AUTOSAR XML (schema 4-2-2)
package /ComponentTypes
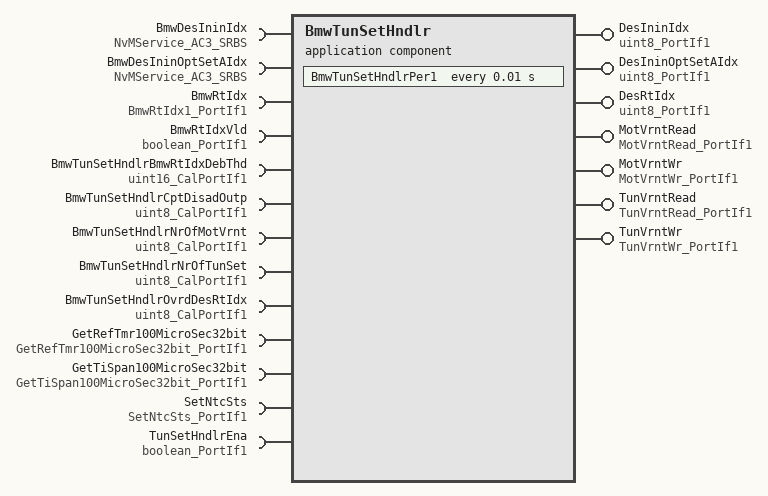
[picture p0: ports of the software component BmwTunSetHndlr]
  application sw component type BmwTunSetHndlr
    7 x provide port:
      DesIninIdx: nonqueued-sender-com-spec{data-element=Val, init-value=0}, provided-interface=uint8_PortIf1
      DesIninOptSetAIdx: nonqueued-sender-com-spec{data-element=Val, init-value=0}, provided-interface=uint8_PortIf1
      DesRtIdx: nonqueued-sender-com-spec{data-element=Val, init-value=0}, provided-interface=uint8_PortIf1
      MotVrntRead: server-com-spec{operation=Oper, queue-length=1}, provided-interface=MotVrntRead_PortIf1
      MotVrntWr: server-com-spec{operation=Oper, queue-length=1}, provided-interface=MotVrntWr_PortIf1
      TunVrntRead: server-com-spec{operation=Oper, queue-length=1}, provided-interface=TunVrntRead_PortIf1
      TunVrntWr: server-com-spec{operation=Oper, queue-length=1}, provided-interface=TunVrntWr_PortIf1
    13 x require port:
      BmwDesIninIdx: required-com-specs=[EraseBlock, GetErrorStatus, InvalidateNvBlock, ReadBlock, SetRamBlockStatus, WriteBlock], required-interface=NvMService_AC3_SRBS
      BmwDesIninOptSetAIdx: required-com-specs=[EraseBlock, GetErrorStatus, InvalidateNvBlock, ReadBlock, SetRamBlockStatus, WriteBlock], required-interface=NvMService_AC3_SRBS
      BmwRtIdx: nonqueued-receiver-com-spec{data-element=Val, filter=data-filter-type=ALWAYS, init-value=15}, required-interface=BmwRtIdx1_PortIf1
      BmwRtIdxVld: nonqueued-receiver-com-spec{data-element=Logl, filter=data-filter-type=ALWAYS, init-value=0}, required-interface=boolean_PortIf1
      BmwTunSetHndlrBmwRtIdxDebThd: parameter-require-com-spec{init-value=120, parameter=Val}, required-interface=uint16_CalPortIf1
      BmwTunSetHndlrCptDisadOutp: parameter-require-com-spec{init-value=0, parameter=Val}, required-interface=uint8_CalPortIf1
      BmwTunSetHndlrNrOfMotVrnt: parameter-require-com-spec{init-value=4, parameter=Val}, required-interface=uint8_CalPortIf1
      BmwTunSetHndlrNrOfTunSet: parameter-require-com-spec{init-value=7, parameter=Val}, required-interface=uint8_CalPortIf1
      BmwTunSetHndlrOvrdDesRtIdx: parameter-require-com-spec{init-value=5, parameter=Val}, required-interface=uint8_CalPortIf1
      GetRefTmr100MicroSec32bit: client-com-spec=Oper, required-interface=GetRefTmr100MicroSec32bit_PortIf1
      GetTiSpan100MicroSec32bit: client-com-spec=Oper, required-interface=GetTiSpan100MicroSec32bit_PortIf1
      SetNtcSts: client-com-spec=Oper, required-interface=SetNtcSts_PortIf1
      TunSetHndlrEna: nonqueued-receiver-com-spec{data-element=Logl, filter=data-filter-type=ALWAYS, init-value=1}, required-interface=boolean_PortIf1
    behavior BmwTunSetHndlr_InternalBehavior
      ar-typed-per-instance-memorys:
        6 x data, all with sw-calibration-access=READ-ONLY:
          BmwDesIninIdx: type=BmwDesIninIdxRec1
          BmwDesIninOptSetAIdx: type=BmwDesIninOptSetAIdxRec1
          BmwRtIdxTi: type=uint32
          DebBmwRtIdx: type=BmwRtIdx1
          LstVldIdx: type=uint8
          PrevBmwRtIdx: type=BmwRtIdx1
      init event BmwTunSetHndlr_InitEvent: start-on-event=BmwTunSetHndlrInit1
      timing event TMT_BmwTunSetHndlrPer1: start-on-event=BmwTunSetHndlrPer1, period=0.01
      4 x operation invoked event:
        OIT_MotVrntRead_Oper_MotVrntRead_Oper: start-on-event=MotVrntRead_Oper, operation=MotVrntRead.Oper
        OIT_MotVrntWr_Oper_MotVrntWr_Oper: start-on-event=MotVrntWr_Oper, operation=MotVrntWr.Oper
        OIT_TunVrntRead_Oper_TunVrntRead_Oper: start-on-event=TunVrntRead_Oper, operation=TunVrntRead.Oper
        OIT_TunVrntWr_Oper_TunVrntWr_Oper: start-on-event=TunVrntWr_Oper, operation=TunVrntWr.Oper
      port-api-options:
        enable-take-address=false, error-handling=NO-TRANSFORMER-ERROR-HANDLING, indirect-api=false, port=BmwDesIninIdx
        enable-take-address=false, error-handling=NO-TRANSFORMER-ERROR-HANDLING, indirect-api=false, port=BmwRtIdx
        enable-take-address=false, error-handling=NO-TRANSFORMER-ERROR-HANDLING, indirect-api=false, port=BmwRtIdxVld
        enable-take-address=false, error-handling=NO-TRANSFORMER-ERROR-HANDLING, indirect-api=false, port=BmwTunSetHndlrBmwRtIdxDebThd
        enable-take-address=false, error-handling=NO-TRANSFORMER-ERROR-HANDLING, indirect-api=false, port=BmwTunSetHndlrCptDisadOutp
        enable-take-address=false, error-handling=NO-TRANSFORMER-ERROR-HANDLING, indirect-api=false, port=BmwTunSetHndlrNrOfMotVrnt
        enable-take-address=false, error-handling=NO-TRANSFORMER-ERROR-HANDLING, indirect-api=false, port=BmwTunSetHndlrOvrdDesRtIdx
        enable-take-address=false, error-handling=NO-TRANSFORMER-ERROR-HANDLING, indirect-api=false, port=DesIninIdx
        enable-take-address=false, error-handling=NO-TRANSFORMER-ERROR-HANDLING, indirect-api=false, port=DesIninOptSetAIdx
        enable-take-address=false, error-handling=NO-TRANSFORMER-ERROR-HANDLING, indirect-api=false, port=DesRtIdx
        enable-take-address=false, error-handling=NO-TRANSFORMER-ERROR-HANDLING, indirect-api=false, port=GetRefTmr100MicroSec32bit
        enable-take-address=false, error-handling=NO-TRANSFORMER-ERROR-HANDLING, indirect-api=false, port=GetTiSpan100MicroSec32bit
        enable-take-address=false, error-handling=NO-TRANSFORMER-ERROR-HANDLING, indirect-api=false, port=MotVrntRead
        enable-take-address=false, error-handling=NO-TRANSFORMER-ERROR-HANDLING, indirect-api=false, port=SetNtcSts
        enable-take-address=false, error-handling=NO-TRANSFORMER-ERROR-HANDLING, indirect-api=false, port=TunSetHndlrEna
        enable-take-address=false, error-handling=NO-TRANSFORMER-ERROR-HANDLING, indirect-api=false, port=TunVrntRead
        enable-take-address=false, error-handling=NO-TRANSFORMER-ERROR-HANDLING, indirect-api=false, port=TunVrntWr
      6 x runnable:
        BmwTunSetHndlrInit1
          data-send-points:
            access SEND_DesIninIdx_Val: accessed-variable=DesIninIdx.Val
            access SEND_DesIninOptSetAIdx_Val: accessed-variable=DesIninOptSetAIdx.Val
          5 x sync call, all with timeout=0:
            SC_BmwDesIninIdx_GetErrorStatus: operation=BmwDesIninIdx.GetErrorStatus
            SC_BmwDesIninIdx_SetRamBlockStatus: operation=BmwDesIninIdx.SetRamBlockStatus
            SC_BmwDesIninOptSetAIdx_GetErrorStatus: operation=BmwDesIninOptSetAIdx.GetErrorStatus
            SC_BmwDesIninOptSetAIdx_SetRamBlockStatus: operation=BmwDesIninOptSetAIdx.SetRamBlockStatus
            SC_SetNtcSts_Oper: operation=SetNtcSts.Oper
        BmwTunSetHndlrPer1
          data-receive-point-by-arguments:
            access REC_BmwRtIdx_Val: accessed-variable=BmwRtIdx.Val
            access REC_BmwRtIdxVld_Logl: accessed-variable=BmwRtIdxVld.Logl
            access REC_TunSetHndlrEna_Logl: accessed-variable=TunSetHndlrEna.Logl
          data-send-points:
            access SEND_DesRtIdx_Val: accessed-variable=DesRtIdx.Val
          sync call SC_GetRefTmr100MicroSec32bit_Oper: operation=GetRefTmr100MicroSec32bit.Oper, timeout=0
          sync call SC_GetTiSpan100MicroSec32bit_Oper: operation=GetTiSpan100MicroSec32bit.Oper, timeout=0
        MotVrntRead_Oper
        MotVrntWr_Oper
          sync call SC_BmwDesIninOptSetAIdx_SetRamBlockStatus: operation=BmwDesIninOptSetAIdx.SetRamBlockStatus, timeout=0
          sync call SC_SetNtcSts_Oper: operation=SetNtcSts.Oper, timeout=0
        TunVrntRead_Oper
        TunVrntWr_Oper
          sync call SC_BmwDesIninIdx_SetRamBlockStatus: operation=BmwDesIninIdx.SetRamBlockStatus, timeout=0
          sync call SC_SetNtcSts_Oper: operation=SetNtcSts.Oper, timeout=0
      swc service dependency NvmBmwDesIninIdx: assigned-ports=role-based-port-assignment={port-prototype=BmwDesIninIdx, role=NvMService_AC3_SRBS}
        assigned-datas:
          role=ramBlock, used-data-element=BmwDesIninIdx
          role=defaultValue, used-parameter-element=BmwDesIninIdxDft
        service-needs:
          nv block needs NvmBmwDesIninIdx: n-data-sets=0, ram-block-status-control=API, readonly=false, reliability=ERROR-DETECTION, resistant-to-changed-sw=true, restore-at-start=true, store-at-shutdown=true, write-only-once=false, writing-frequency=0, writing-priority=LOW
      swc service dependency NvmBmwDesIninOptSetAIdx: assigned-ports=role-based-port-assignment={port-prototype=BmwDesIninOptSetAIdx, role=NvMService_AC3_SRBS}
        assigned-datas:
          role=ramBlock, used-data-element=BmwDesIninOptSetAIdx
          role=defaultValue, used-parameter-element=BmwDesIninOptSetAIdxDft
        service-needs:
          nv block needs NvmBmwDesIninOptSetAIdx: n-data-sets=0, ram-block-status-control=API, readonly=false, reliability=ERROR-DETECTION, resistant-to-changed-sw=true, restore-at-start=true, store-at-shutdown=true, write-only-once=false, writing-frequency=0, writing-priority=LOW
      shared-parameters:
        parameter data prototype BmwDesIninIdxDft: sw-calibration-access=READ-WRITE, type=BmwDesIninIdxRec1, init-value=fields=[BmwDesIninIdx:0, BmwDesIninIdxWrSts:0]
        parameter data prototype BmwDesIninOptSetAIdxDft: sw-calibration-access=READ-WRITE, type=BmwDesIninOptSetAIdxRec1, init-value=fields=[BmwDesIninOptSetAIdx:0, BmwDesIninOptSetAIdxWrSts:0]
  swc implementation BmwTunSetHndlr_Implementation: behavior=BmwTunSetHndlr_InternalBehavior
    code-descriptors:
      code Default: artifact-descriptors=autosar-engineering-object={short-label=Default, category=SWSRC}
